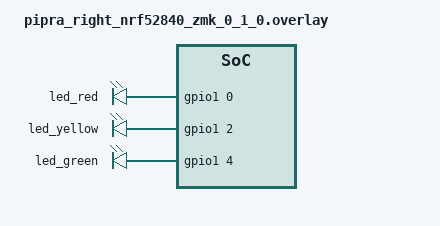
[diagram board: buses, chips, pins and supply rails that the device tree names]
/*
 * Copyright (c) 2025 The ZMK Contributors
 *
 * SPDX-License-Identifier: MIT
 */

&led_red {
    gpios = <&gpio1 0 (GPIO_ACTIVE_HIGH | NRF_GPIO_DRIVE_H0H1)>;
};

&led_yellow {
    gpios = <&gpio1 2 (GPIO_ACTIVE_HIGH | NRF_GPIO_DRIVE_H0H1)>;
};

&led_green {
    gpios = <&gpio1 4 (GPIO_ACTIVE_HIGH | NRF_GPIO_DRIVE_H0H1)>;
};
